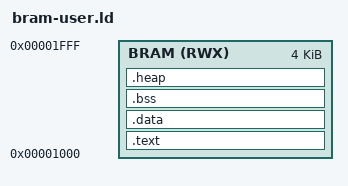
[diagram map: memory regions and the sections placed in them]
MEMORY
{
   BRAM (RWX) : ORIGIN = 0x1000, LENGTH = 0x1000
}
SECTIONS {
    /* The program code and other data goes into BRAM */
    .text :
    {
        . = ALIGN(4);
        crt0-user.o (.text)
        *(.text)           /* .text sections (code) */
        *(.text*)          /* .text* sections (code) */
        *(.rodata)         /* .rodata sections (constants, strings, etc.) */
        *(.rodata*)        /* .rodata* sections (constants, strings, etc.) */
        *(.srodata)        /* .rodata sections (constants, strings, etc.) */
        *(.srodata*)       /* .rodata* sections (constants, strings, etc.) */
        . = ALIGN(4);
        _etext = .;        /* define a global symbol at end of code */
        _sidata = _etext;  /* This is used by the startup in order to initialize the .data secion */
    } >BRAM


    /* This is the initialized data section
    The program executes knowing that the data is in the RAM
    but the loader puts the initial values in the BRAM (inidata).
    It is one task of the startup to copy the initial values from BRAM. */
    .data : AT ( _sidata )
    {
        . = ALIGN(4);
        _sdata = .;        /* create a global symbol at data start; used by startup code in order to initialise the .data section in RAM */
        _ram_start = .;    /* create a global symbol at ram start for garbage collector */
        . = ALIGN(4);
        *(.data)           /* .data sections */
        *(.data*)          /* .data* sections */
        *(.sdata)           /* .sdata sections */
        *(.sdata*)          /* .sdata* sections */
        . = ALIGN(4);
        _edata = .;        /* define a global symbol at data end; used by startup code in order to initialise the .data section in RAM */
    } >BRAM

    /* Uninitialized data section */
    .bss :
    {
        . = ALIGN(4);
        _sbss = .;         /* define a global symbol at bss start; used by startup code */
        *(.bss)
        *(.bss*)
        *(.sbss)
        *(.sbss*)
        *(COMMON)

        . = ALIGN(4);
        _ebss = .;         /* define a global symbol at bss end; used by startup code */
    } >BRAM

    /* this is to define the start of the heap, and make sure we have a minimum size */
    .heap :
    {
        . = ALIGN(4);
        _heap_start = .;    /* define a global symbol at heap start */
    } >BRAM
}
